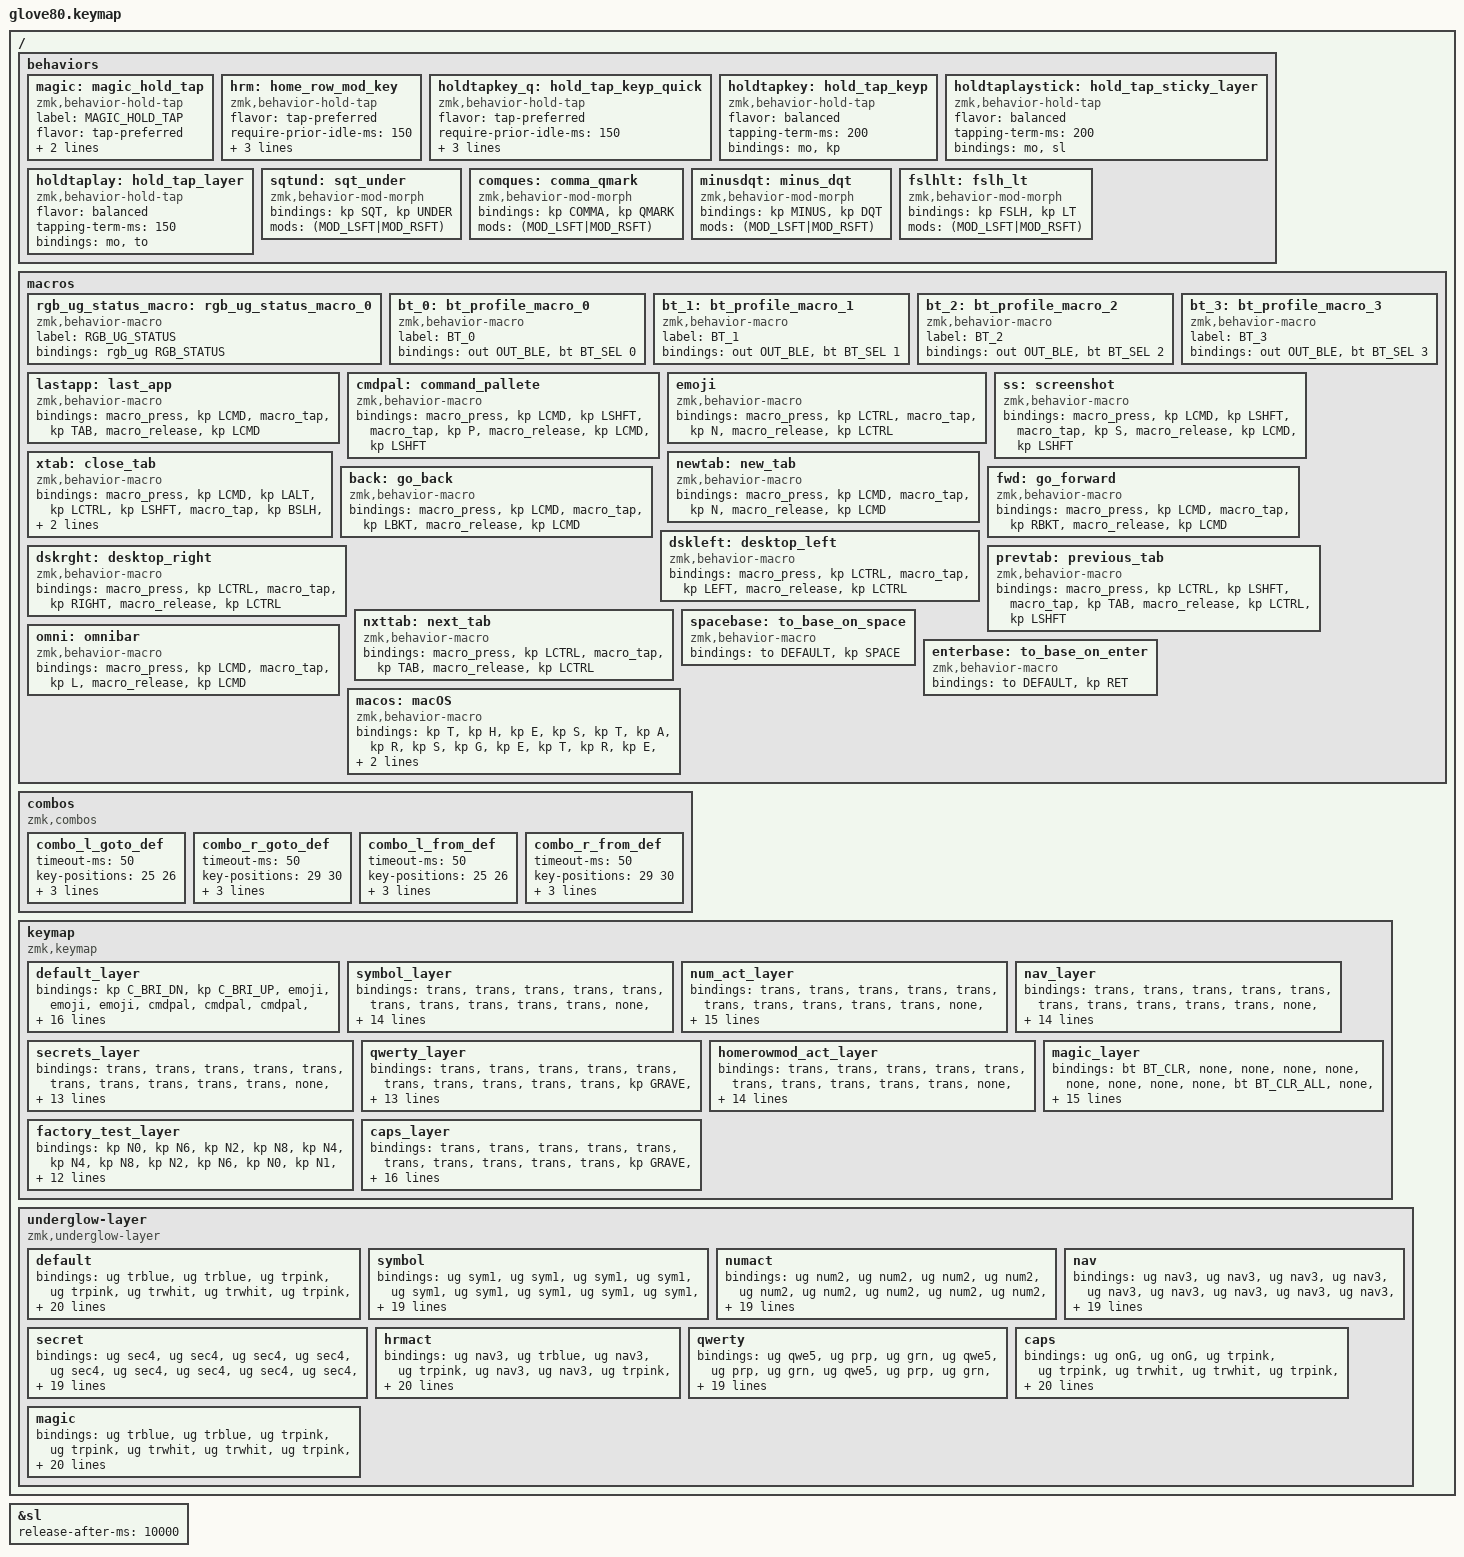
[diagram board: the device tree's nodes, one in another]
/*
* Copyright (c) 2020 The ZMK Contributors
* Copyright (c) 2026 Hazeline Nishad
*
* SPDX-License-Identifier: MIT
* Version: Mark XXVI - 27
*/

#define ZMK_POINTING_DEFAULT_MOVE_VAL 800  // default: 600
#define ZMK_POINTING_DEFAULT_SCRL_VAL 100  

#include <behaviors.dtsi>
#include <dt-bindings/zmk/keys.h>
#include <dt-bindings/zmk/bt.h>
#include <dt-bindings/zmk/ext_power.h>
#include <dt-bindings/zmk/outputs.h>
#include <dt-bindings/zmk/rgb.h>
#include <dt-bindings/zmk/rgb_colors.h>
#include <dt-bindings/zmk/pointing.h>

#define HYPER LC(LS(LG(LALT)))

// ? layers (The numbering HAS to be in order)
#define DEFAULT 0
#define SYMBOL 1
#define NUMACT 2
#define NAV 3
#define SECRET 4
#define QWERTY 5
#define HRMACT 6
#define MAGIC 7
#define FACTORY_TEST 8
#define CAPLAYER 9

// * Sticky Layer auto release
&sl {
	release-after-ms = <10000>;
};


/ {
	behaviors {
		magic: magic_hold_tap {
			compatible = "zmk,behavior-hold-tap";
			label = "MAGIC_HOLD_TAP";
			#binding-cells = <2>;
			flavor = "tap-preferred";
			tapping-term-ms = <200>;
			bindings = <&mo>, <&rgb_ug_status_macro>;
		};
		
		hrm: home_row_mod_key {
			compatible = "zmk,behavior-hold-tap";
			#binding-cells = <2>;
			flavor = "tap-preferred";
			require-prior-idle-ms = <150>;
			tapping-term-ms = <170>;
			quick-tap-ms = <175>;
			bindings = <&kp>, <&kp>;
		};
		
		holdtapkey_q: hold_tap_keyp_quick {
			compatible = "zmk,behavior-hold-tap";
			#binding-cells = <2>;
			flavor = "tap-preferred";
			require-prior-idle-ms = <150>;
			tapping-term-ms = <170>;
			quick-tap-ms = <175>;
			bindings = <&mo>, <&kp>;
		};
		
		holdtapkey: hold_tap_keyp {
			compatible = "zmk,behavior-hold-tap";
			#binding-cells = <2>;
			flavor = "balanced";
			tapping-term-ms = <200>;
			bindings = <&mo>, <&kp>;
		};
		
		holdtaplaystick: hold_tap_sticky_layer {
			compatible = "zmk,behavior-hold-tap";
			#binding-cells = <2>;
			flavor = "balanced";
			tapping-term-ms = <200>;
			bindings = <&mo>, <&sl>;
		};
		
		holdtaplay: hold_tap_layer {
			compatible = "zmk,behavior-hold-tap";
			#binding-cells = <2>;
			flavor = "balanced";
			tapping-term-ms = <150>;
			bindings = <&mo>, <&to>;
		};
		
		sqtund: sqt_under {
			compatible = "zmk,behavior-mod-morph";
			#binding-cells = <0>;
			bindings = <&kp SQT>, <&kp UNDER>;
			mods = <(MOD_LSFT|MOD_RSFT)>;
		};
		
		comques: comma_qmark {
			compatible = "zmk,behavior-mod-morph";
			#binding-cells = <0>;
			bindings = <&kp COMMA>, <&kp QMARK>;
			mods = <(MOD_LSFT|MOD_RSFT)>;
		};
		
		// ! Unused!!
		minusdqt: minus_dqt {
			compatible = "zmk,behavior-mod-morph";
			#binding-cells = <0>;
			bindings = <&kp MINUS>, <&kp DQT>;
			mods = <(MOD_LSFT|MOD_RSFT)>;
		};
		
		fslhlt: fslh_lt {
			compatible = "zmk,behavior-mod-morph";
			#binding-cells = <0>;
			bindings = <&kp FSLH>, <&kp LT>;
			mods = <(MOD_LSFT|MOD_RSFT)>;
		};
	};
	
	macros {
		rgb_ug_status_macro: rgb_ug_status_macro_0 {
			label = "RGB_UG_STATUS";
			compatible = "zmk,behavior-macro";
			#binding-cells = <0>;
			bindings
			= <&rgb_ug RGB_STATUS>;
		};
		
		bt_0: bt_profile_macro_0 {
			label = "BT_0";
			compatible = "zmk,behavior-macro";
			#binding-cells = <0>;
			bindings
			= <&out OUT_BLE>,
			<&bt BT_SEL 0>;
		};
		
		bt_1: bt_profile_macro_1 {
			label = "BT_1";
			compatible = "zmk,behavior-macro";
			#binding-cells = <0>;
			bindings
			= <&out OUT_BLE>,
			<&bt BT_SEL 1>;
		};
		
		bt_2: bt_profile_macro_2 {
			label = "BT_2";
			compatible = "zmk,behavior-macro";
			#binding-cells = <0>;
			bindings
			= <&out OUT_BLE>,
			<&bt BT_SEL 2>;
		};
		
		bt_3: bt_profile_macro_3 {
			label = "BT_3";
			compatible = "zmk,behavior-macro";
			#binding-cells = <0>;
			bindings
			= <&out OUT_BLE>,
			<&bt BT_SEL 3>;
		};
		
		lastapp: last_app {
			compatible = "zmk,behavior-macro";
			#binding-cells = <0>;
			bindings
			= <&macro_press &kp LCMD>
			, <&macro_tap &kp TAB>
			, <&macro_release &kp LCMD>
			;
		};
		
		cmdpal: command_pallete {
			compatible = "zmk,behavior-macro";
			#binding-cells = <0>;
			bindings
			= <&macro_press &kp LCMD &kp LSHFT>
			, <&macro_tap &kp P>
			, <&macro_release &kp LCMD &kp LSHFT>
			;
		};
		
		emoji: emoji {
			compatible = "zmk,behavior-macro";
			#binding-cells = <0>;
			bindings
			= <&macro_press &kp LCTRL>
			, <&macro_tap &kp N>
			, <&macro_release &kp LCTRL>
			;
		};
		
		ss: screenshot {
			compatible = "zmk,behavior-macro";
			#binding-cells = <0>;
			bindings
			= <&macro_press &kp LCMD &kp LSHFT>
			, <&macro_tap &kp S>
			, <&macro_release &kp LCMD &kp LSHFT>
			;
		};
		
		xtab: close_tab {
			compatible = "zmk,behavior-macro";
			#binding-cells = <0>;
			bindings
			= <&macro_press &kp LCMD &kp LALT &kp LCTRL &kp LSHFT>
			, <&macro_tap &kp BSLH>
			, <&macro_release &kp LCMD &kp LALT &kp LCTRL &kp LSHFT>
			;
		};
		
		newtab: new_tab {
			compatible = "zmk,behavior-macro";
			#binding-cells = <0>;
			bindings
			= <&macro_press &kp LCMD>
			, <&macro_tap &kp N>
			, <&macro_release &kp LCMD>
			;
		};
		
		back: go_back {
			compatible = "zmk,behavior-macro";
			#binding-cells = <0>;
			bindings
			= <&macro_press &kp LCMD>
			, <&macro_tap &kp LBKT>
			, <&macro_release &kp LCMD>
			;
		};
		
		fwd: go_forward {
			compatible = "zmk,behavior-macro";
			#binding-cells = <0>;
			bindings
			= <&macro_press &kp LCMD>
			, <&macro_tap &kp RBKT>
			, <&macro_release &kp LCMD>
			;
		};
		
		dskleft: desktop_left {
			compatible = "zmk,behavior-macro";
			#binding-cells = <0>;
			bindings
			= <&macro_press &kp LCTRL>
			, <&macro_tap &kp LEFT>
			, <&macro_release &kp LCTRL>
			;
		};
		
		dskrght: desktop_right {
			compatible = "zmk,behavior-macro";
			#binding-cells = <0>;
			bindings
			= <&macro_press &kp LCTRL>
			, <&macro_tap &kp RIGHT>
			, <&macro_release &kp LCTRL>
			;
		};
		
		prevtab: previous_tab {
			compatible = "zmk,behavior-macro";
			#binding-cells = <0>;
			bindings
			= <&macro_press &kp LCTRL &kp LSHFT>
			, <&macro_tap &kp TAB>
			, <&macro_release &kp LCTRL &kp LSHFT>
			;
		};
		
		nxttab: next_tab {
			compatible = "zmk,behavior-macro";
			#binding-cells = <0>;
			bindings
			= <&macro_press &kp LCTRL>
			, <&macro_tap &kp TAB>
			, <&macro_release &kp LCTRL>
			;
		};
		
		omni: omnibar {
			compatible = "zmk,behavior-macro";
			#binding-cells = <0>;
			bindings
			= <&macro_press &kp LCMD>
			, <&macro_tap &kp L>
			, <&macro_release &kp LCMD>
			;
		};
		
		spacebase: to_base_on_space {
			compatible = "zmk,behavior-macro";
			#binding-cells = <0>;
			bindings
			= <&to DEFAULT>
			, <&kp SPACE>
			;
		};
		
		enterbase: to_base_on_enter {
			compatible = "zmk,behavior-macro";
			#binding-cells = <0>;
			bindings
			= <&to DEFAULT>
			, <&kp RET>
			;
		};
		
		macos: macOS {
			compatible = "zmk,behavior-macro";
			#binding-cells = <0>;
			bindings
			= <&kp T &kp H &kp E &kp S &kp T &kp A &kp R &kp S>
			, <&kp G &kp E &kp T &kp R &kp E &kp A &kp L &kp D &kp A &kp R &kp K &kp N6 &kp DOLLAR>
			, <&macro_wait_time 50>
			, <&kp RET>
			;
		};
		
	};
	
	// * Chord Layer Switch
	combos {
		compatible = "zmk,combos";
		combo_l_goto_def {
			timeout-ms = <50>;
			key-positions = <25 26>;
			bindings = <&to DEFAULT>;
			layers = <1 2 3 4 5 6 7 8>;
			require-prior-idle-ms = <150>;
		};
		
		combo_r_goto_def {
			timeout-ms = <50>;
			key-positions = <29 30>;
			bindings = <&to DEFAULT>;
			layers = <1 2 3 4 5 6 7 8>;
			require-prior-idle-ms = <150>;
		};
		
		combo_l_from_def {
			timeout-ms = <50>;
			key-positions = <25 26>;
			bindings = <&sl SYMBOL>;
			layers = <DEFAULT>;
			require-prior-idle-ms = <150>;
		};
		
		combo_r_from_def {
			timeout-ms = <50>;
			key-positions = <29 30>;
			bindings = <&to NUMACT>;
			layers = <DEFAULT>;
			require-prior-idle-ms = <150>;
		};
	};
	
	keymap {
		compatible = "zmk,keymap";
		
		// - BLANK LAYER: CUSTOMIZE
		// blank_layer {
		// 	bindings = <
		// 	&kp C_BRI_DN         &kp C_BRI_UP   &cmdpal      &emoji      &kp C_MUTE                                 &kp C_PREV  &kp C_PP      &kp C_NEXT      &kp C_VOL_DN      &kp C_VOL_UP
		// 	&trans            &none               &none           &none           &none           &none                         &none     &none   &none 	&none	&none		&none
		// 	&trans            &none               &none           &none          &none           &none                          &none     &none    &none    &none     &none    &none
		// 	&none            &none               &none        &none        &none       &none                                    &none    &none    &none    &none     &none     &none
		// 	&none      &none    &none       &none       &none       &none   &to DEFAULT   &kp LCTRL   &none  			&none  &kp LALT &to DEFAULT   &none   &none   &none   &none     &none    &none
		// 	&trans	 &none 		&none     &none   		 &none           &kp BSPC    &kp LCMD     &none   						&none  &kp RET   &kp SPACE     &none  &none    &none    &none    &none
		// 	>;
		// };
		
		// DONE L0
		default_layer {
			bindings = <
			&kp C_BRI_DN         &kp C_BRI_UP     &emoji     &emoji     &emoji                                                           &cmdpal  &cmdpal    &cmdpal      &kp C_VOL_DN      &kp C_VOL_UP
			&none      &kp N1   &kp N2      &kp N3      &kp N4      &kp N5                                                                     &kp N6  &kp N7  &kp N8      &kp N9      &kp N0      &none
			&kp GRAVE        &kp B    &kp L       &kp D       &hrm LSHIFT W       &kp Z                                                                      &sqtund    &hrm LSHIFT F   &kp O       &kp U       &kp J       &none
			&holdtapkey NAV ESC      &kp N    &kp R       &kp T       &kp S       &kp G                                                                               &kp Y   &kp H   &kp A    &kp E      &kp I    &holdtapkey_q NAV SEMI
			&kp TAB      &kp Q    &holdtapkey_q HRMACT X       &kp M       &kp C       &kp V   &holdtaplaystick SYMBOL SYMBOL   &kp LCTRL   &none         &none  &kp LALT  &to NUMACT          &kp K   &kp P   &kp DOT   &comques  &mkp LCLK    &none
			&magic MAGIC 0 &trans &kp TAB     &kp LEFT    &kp RIGHT           &kp BSPC    &kp LCMD     &kp LALT         &holdtaplay SECRET CAPLAYER  &kp RET   &kp SPACE         &kp UP  &kp DOWN    &trans    &trans &none
			>;
		};
		
		// DONE L1 
		symbol_layer {
			bindings = <
			&trans         &trans   &trans      &trans      &trans                                                								     &trans  &trans      &trans      &trans      &trans
			&none      &none   &kp N2      &kp N3      &kp N4      &kp N5                                                      		&kp N6  &kp N7  &kp N8      &kp N9      &none      &none
			&none            &kp N1           &kp AT        &kp HASH        &kp DOLLAR        &kp PERCENT                       		&kp CARET     &kp AMPERSAND    &kp STAR    &kp EXCL     &kp N0    &none
			&trans            &kp LT               &kp LBKT        &kp LPAR        &kp LBRC       &kp DQT                     		&kp QMARK    &kp RBRC    &kp RPAR    &kp RBKT     &kp GT     &none
			&trans      &none    &kp TILDE       &kp PIPE       &kp UNDER     &kp FSLH   &to DEFAULT   &trans   &trans  		&to DEFAULT  &trans &to NAV   	&kp BSLH   &kp EQUAL   &kp PLUS   &kp COLON  &kp GRAVE    &none
			&trans	 &trans 		&trans     &kp LEFT   		 &kp RIGHT           &trans    &trans    &trans   					&trans  &trans   &trans    	 			&kp MINUS  &kp DOWN    &trans    &trans    &none
			>;
		};
		
		// DONE L2
		num_act_layer {
			bindings = <
			&trans         &trans   &trans      &trans      &trans                                                								          &trans  &trans      &trans      &trans      &trans
			&none            &none               &none           &none           &none           &none                                                   &none     &kp PRCNT   &kp KP_EQUAL      &kp KP_DIVIDE       &none    &none
			&none            &none               &none           &kp C_VOL_DN   &kp C_VOL_UP     &kp C_MUTE                                                  &kp LPAR     &kp KP_N7    &kp KP_N8    &kp KP_N9     &kp KP_MULTIPLY    &none
			&trans            &none               &kp LEFT        &kp C_PREV        &kp C_PP       &kp C_NEXT                                                    &kp RPAR    &kp KP_N4    &kp KP_N5    &kp KP_N6     &kp KP_PLUS     &none
			&trans      &none    &none       &kp C_BRI_DN       &kp C_BRI_UP       &ss   &to DEFAULT   &trans   &trans  			&to DEFAULT  &trans &none  			 &kp COMMA   &kp KP_N1   &kp KP_N2   &kp KP_N3     &kp KP_MINUS    &none
			&trans	 &trans 		&trans     &kp LEFT   		 &kp RIGHT           &trans    &trans     &trans   						&trans  &enterbase   &spacebase 		    &kp KP_N0  &kp KP_DOT    &trans   &trans    &none
			>;
		};
		
		// DONE L3
		nav_layer {
			bindings = <
			&trans         &trans   &trans      &trans      &trans                                                								     &trans  &trans      &trans      &trans      &trans
			&none            &none               &none           &none           &none           &none                                                            &xtab    &none     &none 	   &none	      &none	    	&none
			&none            &none               &msc SCRL_RIGHT           &mmv MOVE_UP          &msc SCRL_LEFT           &mkp RCLK                          &lastapp     &kp LG(LEFT)    &kp UP    &kp LG(RIGHT)     &none    &none
			&trans            &none               &mmv MOVE_LEFT        &mmv MOVE_DOWN        &mmv MOVE_RIGHT       &mkp LCLK                                   &newtab    &kp LEFT    &kp DOWN    &kp RIGHT     &omni     &none
			&trans      &none    &none       &msc SCRL_DOWN       &msc SCRL_UP  &none   		&to DEFAULT &trans   &trans  				&to DEFAULT  &trans &none   	&dskleft   &prevtab   &nxttab   &dskrght     &none    &none
			&trans	 &trans 		&trans     &kp PG_UP    &kp PG_DN          				 &trans    &trans     &trans   								&trans  &trans   &trans    		 &back  &fwd    &trans    &trans    &to SECRET
			>;
		};
		
		// DONE L4
		secrets_layer {
			bindings = <
			&trans         &trans   &trans      &trans      &trans                                                								     &trans  &trans      &trans      &trans      &trans
			&none            &none           &none           &none           &none           &none                         &to QWERTY     &none   &none 	&none	&none		&none
			&none            &none          &kp LC(N7)           &kp LC(N8)          &kp LC(N9)           &kp LC(N0)                          &none     &none    &none    &none     &none    &none
			&trans            &none        &kp LC(N4)        &kp LC(N5)        &kp LC(N6)       &none                                    &to DEFAULT    &macos    &none    &kp LG(LC(Q))     &none     &none
			&trans      &none    &kp LC(N1)       &kp LC(N2)       &kp LC(N3)       &none   &to DEFAULT   &trans   &trans  			&kp C_PREV  &kp C_NEXT &kp C_PP   &none   &none   &none   &none     &none    &none
			&trans	 &trans 		&trans     &trans   		 &trans           &trans    &trans     &trans   						&none  &kp C_VOL_DN   &kp C_VOL_UP     &trans  &trans    &trans    &trans    &none
			>;
		};
		
		// DONE L5
		qwerty_layer {
			bindings = <
			&trans         &trans   &trans      &trans      &trans                                                								     &trans  &trans      &trans      &trans      &trans
			&kp GRAVE      &kp N1   &kp N2      &kp N3      &kp N4      &kp N5                                                                     &kp N6  &kp N7  &kp N8      &kp N9      &kp N0      &none
			&kp BSLH        &kp Q    &kp W       &kp E       &hrm LSHIFT R       &kp T                                                                      &kp Y   &hrm LSHIFT U   &kp I       &kp O       &kp P       &kp EQUAL
			&holdtapkey NAV ESC        &kp A    &kp S       &kp D       &kp F       &kp G                                                                      &kp H   &kp J   &kp K       &kp L       &kp SEMI    &kp SQT
			&kp TAB      &kp Z    &kp X       &kp C       &kp V       &kp B   &to DEFAULT   &trans   &trans     &to DEFAULT  &trans &none   &kp N   &kp M   &kp DOT   &comques     &minusdqt    &fslhlt
			&magic MAGIC 0 &trans &trans     &kp LEFT    &kp RIGHT     &trans    &trans     &trans            &trans  &trans   &trans  &kp UP  &kp DOWN    &kp LBKT    &kp RBKT    &none
			>;
		};
		
		// DONE L6
		homerowmod_act_layer {
			bindings = <
			&trans         &trans   &trans      &trans      &trans                                                								     &trans  &trans      &trans      &trans      &trans
			&none            &none           &none           &none           &none           &none                                          &xtab     &kp LA(Y)   &kp LG(RET) 	&none	&none		&none
			&none            &none          &none           &none          &kp LG(FSLH)           &kp LC(GRAVE)                          &lastapp     &kp LG(LEFT)    &kp TAB    &kp LG(RIGHT)     &none    &none
			&trans            &none        &none        &kp LG(LS(Z))        &kp LG(Z)       &kp LG(A)                                    &newtab    &kp RET    &kp LS(RET)    &kp LG(RET)     &omni     &none
			&trans      &none    &none       &kp LG(X)       &kp LG(C)       &kp LG(V)   &trans   &trans   &trans  			&kp C_PREV  &kp C_NEXT &kp C_PP   &dskleft   &prevtab   &nxttab   &dskrght     &none    &none
			&trans	 &trans 		&trans     &trans   &trans              &kp LC(V)    &kp LA(BSPC)     &trans   						&none  &kp C_VOL_DN   &kp C_VOL_UP     &back  &fwd    &trans    &trans    &none
			>;
		};
		
		magic_layer {
			bindings = <
			&bt BT_CLR        &none               &none           &none           &none                                                                                                           &none      &none      &none      &none      &bt BT_CLR_ALL
			&none             &none               &none           &none           &none           &none                                                                                &none      &none      &none      &none      &none      &none
			&none             &rgb_ug RGB_SPI     &rgb_ug RGB_SAI &rgb_ug RGB_HUI &rgb_ug RGB_BRI &rgb_ug RGB_TOG                                                                      &none      &none      &none      &none      &none      &none
			&bootloader       &rgb_ug RGB_SPD     &rgb_ug RGB_SAD &rgb_ug RGB_HUD &rgb_ug RGB_BRD &rgb_ug RGB_EFF                                                                      &none      &none      &none      &none      &none      &bootloader
			&sys_reset        &none               &none           &none           &none           &none           &bt_2     &bt_3     &none            &none     &none     &none       &none      &none      &none      &none      &none      &sys_reset
			&none             &none               &none           &none           &none                           &bt_0     &bt_1     &out OUT_USB     &none     &none     &none                  &none      &none      &none      &none      &to FACTORY_TEST
			>;
		};
		
		factory_test_layer {
			bindings = <
			&kp N0   &kp N6   &kp N2   &kp N8   &kp N4                                                                              &kp N4   &kp N8   &kp N2   &kp N6   &kp N0
			&kp N1   &kp N7   &kp N3   &kp N9   &kp N5   &kp N0                                                            &kp N0   &kp N5   &kp N9   &kp N3   &kp N7   &kp N1
			&kp N2   &kp N8   &kp N4   &kp N0   &kp N6   &kp N1                                                            &kp N1   &kp N6   &kp N0   &kp N4   &kp N8   &kp N2
			&kp N3   &kp N9   &kp N5   &kp N1   &kp N7   &kp N2                                                            &kp N2   &kp N7   &kp N1   &kp N5   &kp N9   &kp N3
			&kp N4   &kp N0   &kp N6   &kp N2   &kp N8   &kp N3   &kp N4   &kp N5   &kp N6      &kp N6   &kp N5   &kp N4   &kp N3   &kp N8   &kp N2   &kp N6   &kp N0   &kp N4
			&kp N5   &kp N1   &kp N7   &kp N3   &kp N9            &kp N7   &kp N8   &kp N9      &kp N9   &kp N8   &kp N7            &kp N9   &kp N3   &kp N7   &kp N1   &kp N5
			>;
		};
		
		// DONE L8
		caps_layer {
			bindings = <
			&trans         &trans   &trans      &trans      &trans                                                								     &trans  &trans      &trans      &trans      &trans
			&kp GRAVE      &kp N1   &kp N2      &kp N3      &kp N4      &kp N5                                                                     &kp N6  &kp N7  &kp N8      &kp N9      &kp N0      &none
			&kp BSLH        &kp LS(B)   &kp LS(L)       &kp LS(D)       &hrm LSHIFT LS(W)       &kp LS(Z)                                                                      &kp UNDER    &hrm LSHIFT LS(F)   &kp LS(O)       &kp LS(U)       &kp LS(J)       &none
			&holdtapkey NAV ESC      &kp LS(N)    &kp LS(R)       &kp LS(T)       &kp LS(S)       &kp LS(G)                                                                      &kp LS(Y)   &kp LS(H)   &kp LS(A)    &kp LS(E)      &kp LS(I)    &kp SEMI
			&kp TAB      &kp LS(Q)    &kp LS(X)       &kp LS(M)       &kp LS(C)       &kp LS(V)   &to DEFAULT   &trans   &trans          &none  &trans &none   &kp LS(K)   &kp LS(P)   &kp DOT   &comques     &minusdqt    &none
			&magic MAGIC 0 &trans &trans     &kp LEFT    &kp RIGHT      &trans    &trans     &trans          &to DEFAULT  &trans   &trans    &kp UP  &kp DOWN    &kp LBKT    &kp RBKT    &none
			>;
		};
		
	};
};

// * Common theming
// #define sym1 0xFFC800// yellow
// #define num2 0x00FF00// green
// #define nav3 0x00FFEA// blue

#define onG 0x00FF00// green
#define sec4 0xFFFFFF// white
#define qwe5 0x0051FF// dark blue

#define red 0xff0000//red
#define grn 0x00FF00// green
#define ylw 0xFBFF00// yellow
#define blu 0x00FFEA// blue
#define blk 0x000000// black
#define prp 0xD900FF// purple

// // * Orange theming
// #define def0 0xFF5E00// main oraage
// #define sym1 0xD900FF// purple
// #define num2 0x00FFEA// blue
// #define nav3 0xFFC800// yellow

// // * Blue theming
// #define def0 0x006EFF// main blue
// #define sym1 0x2900FF// dark blue
// #define num2 0x00FF00// green
// #define nav3 0x00FFEA// blue

// * Magenta theming
// #define def0 0xFF0062// main magenta
// #define sym1 0xFFC800// yellow
// #define num2 0x00FFEA// blue
// #define nav3 0xD900FF// purple

// * Trans theming
#define trblue 0x9FE4FF// trans blue
#define trpink 0xFF89AC// trans pink
#define trwhit 0xFFFFFF// trans white
#define sym1 0x2900FF// dark blue
#define num2 0x00FF00// green
#define nav3 0xFFC800// yellow
#define sec4 0xFF5E00// orange

/ {
	underglow-layer {
		compatible  = "zmk,underglow-layer";
		default {
			bindings = <
			&ug trblue &ug trblue &ug trpink &ug trpink &ug trwhit                                                                                                   &ug trwhit &ug trpink &ug trpink &ug trblue &ug trblue
			&ug trblue &ug trblue &ug trpink &ug trpink &ug trwhit &ug trwhit                                                                             &ug trwhit &ug trwhit &ug trpink &ug trpink &ug trblue &ug trblue
			&ug trblue &ug trblue &ug trpink &ug trpink &ug trwhit &ug trwhit                                                                             &ug trwhit &ug trwhit &ug trpink &ug trpink &ug trblue &ug trblue
			&ug trblue &ug trblue &ug trpink &ug trpink &ug trwhit &ug trwhit                                                                             &ug trwhit &ug trwhit &ug trpink &ug trpink &ug trblue &ug trblue
			&ug trblue &ug trblue &ug trpink &ug trpink &ug trwhit &ug trwhit &ug trblue &ug trpink &ug trwhit 			 &ug trwhit &ug trpink &ug trblue &ug trwhit &ug trwhit &ug trpink &ug trpink &ug trblue &ug trblue
			&ug trblue &ug trblue &ug trpink &ug trpink &ug trwhit            &ug trblue &ug trpink &ug trwhit   		 &ug trwhit &ug trpink &ug trblue            &ug trwhit &ug trpink &ug trpink &ug trblue &ug trblue
			>;
			layer-id = <DEFAULT>;
		};
		symbol {
			bindings = <
			&ug sym1 &ug sym1 &ug sym1 &ug sym1 &ug sym1                                                                             &ug sym1     &ug sym1        &ug sym1       &ug sym1     &ug sym1
			&ug trblue &ug trblue &ug trpink &ug trpink &ug trwhit &ug trwhit                                                                             &ug trwhit &ug trwhit &ug trpink &ug trpink &ug trblue &ug trblue
			&ug trblue &ug trblue &ug trpink &ug trpink &ug trwhit &ug trwhit                                                                             &ug trwhit &ug trwhit &ug trpink &ug trpink &ug trblue &ug trblue
			&ug trblue &ug trblue &ug trpink &ug trpink &ug trwhit &ug trwhit                                                                             &ug trwhit &ug trwhit &ug trpink &ug trpink &ug trblue &ug trblue
			&ug trblue &ug trblue &ug trpink &ug trpink &ug trwhit &ug trwhit &ug trblue &ug trpink &ug trwhit 			 &ug trwhit &ug trpink &ug trblue &ug trwhit &ug trwhit &ug trpink &ug trpink &ug trblue &ug trblue
			&ug trblue &ug trblue &ug trpink &ug trpink &ug trwhit            &ug trblue &ug trpink &ug trwhit   		 &ug trwhit &ug trpink &ug trblue            &ug trwhit &ug trpink &ug trpink &ug trblue &ug trblue
			>;
			layer-id = <SYMBOL>;
		};
		numact {
			bindings = <
			&ug num2 &ug num2 &ug num2 &ug num2 &ug num2                                                                             &ug num2     &ug num2        &ug num2       &ug num2     &ug num2
			&ug trblue &ug trblue &ug trpink &ug trpink &ug trwhit &ug trwhit                                                                             &ug trwhit &ug trwhit &ug trpink &ug trpink &ug trblue &ug trblue
			&ug trblue &ug trblue &ug trpink &ug trpink &ug trwhit &ug trwhit                                                                             &ug trwhit &ug trwhit &ug trpink &ug trpink &ug trblue &ug trblue
			&ug trblue &ug trblue &ug trpink &ug trpink &ug trwhit &ug trwhit                                                                             &ug trwhit &ug trwhit &ug trpink &ug trpink &ug trblue &ug trblue
			&ug trblue &ug trblue &ug trpink &ug trpink &ug trwhit &ug trwhit &ug trblue &ug trpink &ug trwhit 			 &ug trwhit &ug trpink &ug trblue &ug trwhit &ug trwhit &ug trpink &ug trpink &ug trblue &ug trblue
			&ug trblue &ug trblue &ug trpink &ug trpink &ug trwhit            &ug trblue &ug trpink &ug trwhit   		 &ug trwhit &ug trpink &ug trblue            &ug trwhit &ug trpink &ug trpink &ug trblue &ug trblue
			>;
			layer-id = <NUMACT>;
		};
		nav {
			bindings = <
			&ug nav3 &ug nav3 &ug nav3 &ug nav3 &ug nav3                                                                             &ug nav3     &ug nav3        &ug nav3       &ug nav3     &ug nav3
			&ug trblue &ug trblue &ug trpink &ug trpink &ug trwhit &ug trwhit                                                                             &ug trwhit &ug trwhit &ug trpink &ug trpink &ug trblue &ug trblue
			&ug trblue &ug trblue &ug trpink &ug trpink &ug trwhit &ug trwhit                                                                             &ug trwhit &ug trwhit &ug trpink &ug trpink &ug trblue &ug trblue
			&ug trblue &ug trblue &ug trpink &ug trpink &ug trwhit &ug trwhit                                                                             &ug trwhit &ug trwhit &ug trpink &ug trpink &ug trblue &ug trblue
			&ug trblue &ug trblue &ug trpink &ug trpink &ug trwhit &ug trwhit &ug trblue &ug trpink &ug trwhit 			 &ug trwhit &ug trpink &ug trblue &ug trwhit &ug trwhit &ug trpink &ug trpink &ug trblue &ug trblue
			&ug trblue &ug trblue &ug trpink &ug trpink &ug trwhit            &ug trblue &ug trpink &ug trwhit   		 &ug trwhit &ug trpink &ug trblue            &ug trwhit &ug trpink &ug trpink &ug trblue &ug trblue
			>;
			layer-id = <NAV>;
		};
		secret {
			bindings = <
			&ug sec4 &ug sec4 &ug sec4 &ug sec4 &ug sec4                                                                             &ug sec4     &ug sec4        &ug sec4       &ug sec4     &ug sec4
			&ug trblue &ug trblue &ug trpink &ug trpink &ug trwhit &ug trwhit                                                                             &ug trwhit &ug trwhit &ug trpink &ug trpink &ug trblue &ug trblue
			&ug trblue &ug trblue &ug trpink &ug trpink &ug trwhit &ug trwhit                                                                             &ug trwhit &ug trwhit &ug trpink &ug trpink &ug trblue &ug trblue
			&ug trblue &ug trblue &ug trpink &ug trpink &ug trwhit &ug trwhit                                                                             &ug trwhit &ug trwhit &ug trpink &ug trpink &ug trblue &ug trblue
			&ug trblue &ug trblue &ug trpink &ug trpink &ug trwhit &ug trwhit &ug trblue &ug trpink &ug trwhit 			        &ug sec4 &ug sec4 &ug blk &ug trwhit &ug trwhit &ug trpink &ug trpink &ug trblue &ug trblue
			&ug trblue &ug trblue &ug trpink &ug trpink &ug trwhit            &ug trblue &ug trpink &ug trwhit   		        &ug trwhit &ug grn &ug grn           &ug trwhit &ug trpink &ug trpink &ug trblue &ug trblue
			>;
			layer-id = <SECRET>;
		};
		hrmact {
			bindings = <
			&ug nav3 &ug trblue &ug nav3 &ug trpink &ug nav3                                                                             &ug nav3     &ug trpink        &ug nav3       &ug trblue     &ug nav3
			&ug trblue &ug trblue &ug trpink &ug trpink &ug trwhit &ug trwhit                                                                                 &ug trwhit &ug trwhit &ug trpink &ug trpink &ug trblue &ug trblue
			&ug trblue &ug trblue &ug trpink &ug trpink &ug trwhit &ug trwhit                                                                                 &ug trwhit &ug trwhit &ug trpink &ug trpink &ug trblue &ug trblue
			&ug trblue &ug trblue &ug trpink &ug trpink &ug trwhit &ug trwhit                                                                                 &ug trwhit &ug trwhit &ug trpink &ug trpink &ug trblue &ug trblue
			&ug trblue &ug trblue &ug trpink &ug trpink &ug trwhit &ug trwhit &ug trblue &ug trpink &ug trwhit 			 &ug nav3 &ug nav3 &ug blk &ug trwhit &ug trwhit &ug trpink &ug trpink &ug trblue &ug trblue
			&ug trblue &ug trblue &ug trpink &ug trpink &ug trwhit            &ug trblue &ug trpink &ug trwhit   		 &ug trwhit &ug grn &ug grn           &ug trwhit &ug trpink &ug trpink &ug trblue &ug trblue
			>;
			layer-id = <HRMACT>;
		};
		qwerty {
			bindings = <
			&ug qwe5 &ug prp &ug grn &ug qwe5 &ug prp                                                                             &ug grn     &ug qwe5        &ug prp       &ug grn     &ug qwe5
			&ug trblue &ug trblue &ug trpink &ug trpink &ug trwhit &ug trwhit                                                                             &ug trwhit &ug trwhit &ug trpink &ug trpink &ug trblue &ug trblue
			&ug trblue &ug trblue &ug trpink &ug trpink &ug trwhit &ug trwhit                                                                             &ug trwhit &ug trwhit &ug trpink &ug trpink &ug trblue &ug trblue
			&ug trblue &ug trblue &ug trpink &ug trpink &ug trwhit &ug trwhit                                                                             &ug trwhit &ug trwhit &ug trpink &ug trpink &ug trblue &ug trblue
			&ug trblue &ug trblue &ug trpink &ug trpink &ug trwhit &ug trwhit &ug trblue &ug trpink &ug trwhit 			 &ug trwhit &ug trpink &ug trblue &ug trwhit &ug trwhit &ug trpink &ug trpink &ug trblue &ug trblue
			&ug trblue &ug trblue &ug trpink &ug trpink &ug trwhit            &ug trblue &ug trpink &ug trwhit   		 &ug trwhit &ug trpink &ug trblue            &ug trwhit &ug trpink &ug trpink &ug trblue &ug trblue
			>;
			layer-id = <QWERTY>;
		};
		caps {
			bindings = <
			&ug onG    &ug onG    &ug trpink &ug trpink &ug trwhit                                                                                                   &ug trwhit &ug trpink &ug trpink &ug onG    &ug onG
			&ug trblue &ug trblue &ug trpink &ug trpink &ug trwhit &ug trwhit                                                                             &ug trwhit &ug trwhit &ug trpink &ug trpink &ug trblue &ug trblue
			&ug trblue &ug trblue &ug trpink &ug trpink &ug trwhit &ug trwhit                                                                             &ug trwhit &ug trwhit &ug trpink &ug trpink &ug trblue &ug trblue
			&ug trblue &ug trblue &ug trpink &ug trpink &ug trwhit &ug trwhit                                                                             &ug trwhit &ug trwhit &ug trpink &ug trpink &ug trblue &ug trblue
			&ug trblue &ug trblue &ug trpink &ug trpink &ug trwhit &ug trwhit &ug trblue &ug trpink &ug trwhit 			 &ug trwhit &ug trpink &ug trblue &ug trwhit &ug trwhit &ug trpink &ug trpink &ug trblue &ug trblue
			&ug trblue &ug trblue &ug trpink &ug trpink &ug trwhit            &ug trblue &ug trpink &ug trwhit   		 &ug onG &ug trpink &ug trblue               &ug trwhit &ug trpink &ug trpink &ug trblue &ug trblue
			>;
			layer-id = <CAPLAYER>;
		};
		magic {
			bindings = <
			&ug trblue &ug trblue &ug trpink &ug trpink &ug trwhit                                                                                        &ug trwhit &ug trpink &ug trpink &ug trblue &ug trblue
			&ug trblue &ug trblue &ug trpink &ug trpink &ug trwhit &ug trwhit                                                                  &ug trwhit &ug trwhit &ug trpink &ug trpink &ug trblue &ug trblue
			&ug trblue &ug trblue &ug trpink &ug trpink &ug trwhit &ug trwhit                                                                  &ug trwhit &ug trwhit &ug trpink &ug trpink &ug trblue &ug trblue
			&ug trblue &ug trblue &ug trpink &ug trpink &ug trwhit &ug trwhit                                                                  &ug trwhit &ug trwhit &ug trpink &ug trpink &ug trblue &ug trblue
			&ug trblue &ug trblue &ug trpink &ug trpink &ug trwhit &ug trwhit &ug trblue &ug trpink &ug trwhit 			 &ug trwhit &ug trpink &ug trblue &ug trwhit &ug trwhit &ug trpink &ug trpink &ug trblue &ug trblue
			&ug trblue &ug trblue &ug trpink &ug trpink &ug trwhit            &ug trblue &ug trpink &ug trwhit   		 &ug trwhit &ug trpink &ug trblue            &ug trwhit &ug trpink &ug trpink &ug trblue &ug trblue
			>;
			layer-id = <MAGIC>;
		};
		
		// ! The original color coding
		// default {
		// 	bindings = <
		// 	&ug def0 &ug def0 &ug def0 &ug def0 &ug def0                                                                             &ug def0     &ug def0        &ug def0       &ug def0     &ug def0
		// 	&ug def0  &ug def0    &ug def0    &ug def0 &ug def0    &ug def0                                                            &ug def0 &ug def0 &ug def0        &ug def0        &ug def0  &ug def0
		// 	&ug def0  &ug def0    &ug def0    &ug def0 &ug def0    &ug def0                                                            &ug def0 &ug def0   &ug def0 &ug def0 &ug def0  &ug def0
		// 	&ug def0  &ug def0    &ug def0    &ug def0 &ug def0 &ug def0                                                            &ug def0 &ug def0   &ug def0 &ug def0 &ug def0  &ug def0
		// 	&ug def0  &ug def0 &ug def0    &ug def0 &ug def0 &ug def0 &ug def0 &ug def0 &ug def0 			&ug def0 &ug def0 &ug def0 &ug def0 &ug def0   &ug def0 &ug def0 &ug def0  &ug def0
		// 	&ug def0 &ug def0 &ug def0 &ug def0 &ug def0   &ug def0 	&ug def0 &ug def0   				&ug def0 &ug def0 &ug def0  &ug def0   &ug def0 &ug def0  &ug def0  &ug def0
		// 	>;
		// 	layer-id = <DEFAULT>;
		// };
		// symbol {
		// 	bindings = <
		// 	&ug sym1 &ug sym1 &ug sym1 &ug sym1 &ug sym1                                                                             &ug sym1     &ug sym1        &ug sym1       &ug sym1     &ug sym1
		// 	&ug def0  &ug def0    &ug def0    &ug def0 &ug def0    &ug def0                                                            &ug def0 &ug def0 &ug def0        &ug def0        &ug def0  &ug def0
		// 	&ug def0  &ug def0    &ug def0    &ug def0 &ug def0    &ug def0                                                            &ug def0 &ug def0   &ug def0 &ug def0 &ug def0  &ug def0
		// 	&ug def0  &ug def0    &ug def0    &ug def0 &ug def0 &ug def0                                                            &ug def0 &ug def0   &ug def0 &ug def0 &ug def0  &ug def0
		// 	&ug def0  &ug def0 &ug def0    &ug def0 &ug def0 &ug def0 &ug def0 &ug def0 &ug def0 			&ug def0 &ug def0 &ug def0 &ug def0 &ug def0   &ug def0 &ug def0 &ug def0  &ug def0
		// 	&ug def0 &ug def0 &ug def0 &ug def0 &ug def0   &ug def0  	&ug def0 &ug def0   				&ug def0 &ug def0 &ug def0  &ug def0   &ug def0 &ug def0  &ug def0  &ug def0
		// 	>;
		// 	layer-id = <SYMBOL>;
		// };
		// numact {
		// 	bindings = <
		// 	&ug num2 &ug num2 &ug num2 &ug num2 &ug num2                                                                             &ug num2     &ug num2        &ug num2       &ug num2     &ug num2
		// 	&ug def0  &ug def0    &ug def0    &ug def0 &ug def0    &ug def0                                                            &ug def0 &ug def0 &ug def0        &ug def0        &ug def0  &ug def0
		// 	&ug def0  &ug def0    &ug def0    &ug def0 &ug def0    &ug def0                                                            &ug def0 &ug def0   &ug def0 &ug def0 &ug def0  &ug def0
		// 	&ug def0  &ug def0    &ug def0    &ug def0 &ug def0 &ug def0                                                            &ug def0 &ug def0   &ug def0 &ug def0 &ug def0  &ug def0
		// 	&ug def0  &ug def0 &ug def0    &ug def0 &ug def0 &ug def0 &ug def0 &ug def0 &ug def0 			&ug def0 &ug def0 &ug def0 &ug def0 &ug def0   &ug def0 &ug def0 &ug def0  &ug def0
		// 	&ug def0 &ug def0 &ug def0 &ug def0 &ug def0   &ug def0  &ug def0 &ug def0   					&ug def0 &ug def0 &ug def0  &ug def0   &ug def0 &ug def0  &ug def0  &ug def0
		// 	>;
		// 	layer-id = <NUMACT>;
		// };
		// nav {
		// 	bindings = <
		// 	&ug nav3 &ug nav3 &ug nav3 &ug nav3 &ug nav3                                                                             &ug nav3     &ug nav3        &ug nav3       &ug nav3     &ug nav3
		// 	&ug def0  &ug def0    &ug def0    &ug def0 &ug def0    &ug def0                                                            &ug def0 &ug def0 &ug def0        &ug def0        &ug def0  &ug def0
		// 	&ug def0  &ug def0    &ug def0    &ug def0 &ug def0    &ug def0                                                            &ug def0 &ug def0   &ug def0 &ug def0 &ug def0  &ug def0
		// 	&ug def0  &ug def0    &ug def0    &ug def0 &ug def0 &ug def0                                                            &ug def0 &ug def0   &ug def0 &ug def0 &ug def0  &ug def0
		// 	&ug def0  &ug def0 &ug def0    &ug def0 &ug def0 &ug def0 &ug def0 &ug def0 &ug def0 			&ug def0 &ug def0 &ug def0 &ug def0 &ug def0   &ug def0 &ug def0 &ug def0  &ug def0
		// 	&ug def0 &ug def0 &ug def0 &ug def0 &ug def0   &ug def0  	&ug def0 &ug def0   				&ug def0 &ug def0 &ug def0  &ug def0   &ug def0 &ug def0  &ug def0  &ug def0
		// 	>;
		// 	layer-id = <NAV>;
		// };
		// secret {
		// 	bindings = <
		// 	&ug sec4 &ug sec4 &ug sec4 &ug sec4 &ug sec4                                                                             &ug sec4     &ug sec4        &ug sec4       &ug sec4     &ug sec4
		// 	&ug def0  &ug def0    &ug def0    &ug def0 &ug def0    &ug def0                                                            &ug def0 &ug def0 &ug def0        &ug def0        &ug def0  &ug def0
		// 	&ug def0  &ug def0    &ug sec4    &ug sec4 &ug sec4    &ug sec4                                                            &ug def0 &ug def0   &ug def0 &ug def0 &ug def0  &ug def0
		// 	&ug def0  &ug def0    &ug sec4    &ug sec4 &ug sec4 &ug def0                                                            &ug def0 &ug def0   &ug def0 &ug def0 &ug def0  &ug def0
		// 	&ug def0  &ug def0 &ug sec4    &ug sec4 &ug sec4 &ug def0 &ug def0 &ug def0 &ug def0 			&ug sec4 &ug sec4 &ug blk &ug def0 &ug def0   &ug def0 &ug def0 &ug def0  &ug def0
		// 	&ug def0 &ug def0 &ug def0 &ug def0 &ug def0   &ug def0  	&ug def0 &ug def0   				&ug def0 &ug grn &ug grn  &ug def0   &ug def0 &ug def0  &ug def0  &ug def0
		// 	>;
		// 	layer-id = <SECRET>;
		// };
		// hrmact {
		// 	bindings = <
		// 	&ug nav3 &ug def0 &ug nav3 &ug def0 &ug nav3                                                                             &ug nav3     &ug def0        &ug nav3       &ug def0     &ug nav3
		// 	&ug def0  &ug def0    &ug def0    &ug def0 &ug def0    &ug def0                                                            &ug def0 &ug def0 &ug def0        &ug def0        &ug def0  &ug def0
		// 	&ug def0  &ug def0    &ug def0    &ug def0 &ug def0    &ug def0                                                            &ug def0 &ug def0   &ug def0 &ug def0 &ug def0  &ug def0
		// 	&ug def0  &ug def0    &ug def0    &ug def0 &ug def0 &ug def0                                                            &ug def0 &ug def0   &ug def0 &ug def0 &ug def0  &ug def0
		// 	&ug def0  &ug def0 &ug def0    &ug def0 &ug def0 &ug def0 &ug def0 &ug def0 &ug def0 			&ug nav3 &ug nav3 &ug blk &ug def0 &ug def0   &ug def0 &ug def0 &ug def0  &ug def0
		// 	&ug def0 &ug def0 &ug def0 &ug def0 &ug def0   &ug def0  	&ug def0 &ug def0   				&ug def0 &ug grn &ug grn  &ug def0   &ug def0 &ug def0  &ug def0  &ug def0
		// 	>;
		// 	layer-id = <HRMACT>;
		// };
		// qwerty {
		// 	bindings = <
		// 	&ug qwe5 &ug prp &ug grn &ug qwe5 &ug prp                                                                             &ug grn     &ug qwe5        &ug prp       &ug grn     &ug qwe5
		// 	&ug def0  &ug def0    &ug def0    &ug def0 &ug def0    &ug def0                                                            &ug def0 &ug def0 &ug def0        &ug def0        &ug def0  &ug def0
		// 	&ug def0  &ug def0    &ug def0    &ug def0 &ug def0    &ug def0                                                            &ug def0 &ug def0   &ug def0 &ug def0 &ug def0  &ug def0
		// 	&ug def0  &ug def0    &ug def0    &ug def0 &ug def0 &ug def0                                                            &ug def0 &ug def0   &ug def0 &ug def0 &ug def0  &ug def0
		// 	&ug def0  &ug def0 &ug def0    &ug def0 &ug def0 &ug def0 &ug def0 &ug def0 &ug def0 			&ug def0 &ug def0 &ug def0 &ug def0 &ug def0   &ug def0 &ug def0 &ug def0  &ug def0
		// 	&ug def0 &ug def0 &ug def0 &ug def0 &ug def0   &ug def0 	&ug def0 &ug def0   				&ug def0 &ug def0 &ug def0  &ug def0   &ug def0 &ug def0  &ug def0  &ug def0
		// 	>;
		// 	layer-id = <QWERTY>;
		// };
		// caps {
		// 	bindings = <
		// 	&ug onG &ug onG &ug def0 &ug def0 &ug def0                                                                             &ug def0     &ug def0        &ug def0       &ug onG     &ug onG
		// 	&ug def0  &ug def0    &ug def0    &ug def0 &ug def0    &ug def0                                                            &ug def0 &ug def0 &ug def0        &ug def0        &ug def0  &ug def0
		// 	&ug def0  &ug def0    &ug def0    &ug def0 &ug def0    &ug def0                                                            &ug def0 &ug def0   &ug def0 &ug def0 &ug def0  &ug def0
		// 	&ug def0  &ug def0    &ug def0    &ug def0 &ug def0 &ug def0                                                            &ug def0 &ug def0   &ug def0 &ug def0 &ug def0  &ug def0
		// 	&ug def0  &ug def0 &ug def0    &ug def0 &ug def0 &ug def0 &ug def0 &ug def0 &ug def0 			&ug def0 &ug def0 &ug def0 &ug def0 &ug def0   &ug def0 &ug def0 &ug def0  &ug def0
		// 	&ug def0 &ug def0 &ug def0 &ug def0 &ug def0   &ug def0 &ug def0 &ug def0   					&ug onG &ug def0 &ug def0  &ug def0   &ug def0 &ug def0  &ug def0  &ug def0
		// 	>;
		// 	layer-id = <CAPLAYER>;
		// };
		// magic {
		// 	bindings = <
		// 	&ug def0 &ug def0 &ug def0 &ug def0 &ug def0                                                                             &ug def0     &ug def0        &ug def0       &ug def0     &ug def0
		// 	&ug def0  &ug def0    &ug def0    &ug def0 &ug def0    &ug def0                                                            &ug def0 &ug def0 &ug def0        &ug def0        &ug def0  &ug def0
		// 	&ug def0  &ug def0    &ug def0    &ug def0 &ug def0    &ug def0                                                            &ug def0 &ug def0   &ug def0 &ug def0 &ug def0  &ug def0
		// 	&ug def0  &ug def0    &ug def0    &ug def0 &ug def0 &ug def0                                                            &ug def0 &ug def0   &ug def0 &ug def0 &ug def0  &ug def0
		// 	&ug def0  &ug def0 &ug def0    &ug def0 &ug def0 &ug def0 &ug def0 &ug def0 &ug def0 			&ug def0 &ug def0 &ug def0 &ug def0 &ug def0   &ug def0 &ug def0 &ug def0  &ug def0
		// 	&ug def0 &ug def0 &ug def0 &ug def0 &ug def0   &ug def0 &ug def0 &ug def0   					&ug def0 &ug def0 &ug def0  &ug def0   &ug def0 &ug def0  &ug def0  &ug def0
		// 	>;
		// 	layer-id = <MAGIC>;
		// };
	};
};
